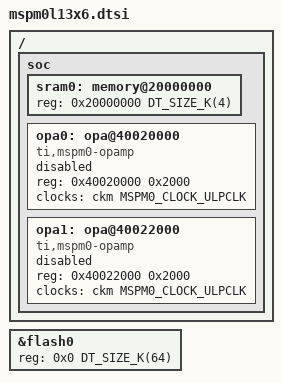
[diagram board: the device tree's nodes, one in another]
/*
 * Copyright (c) 2025 Texas Instruments
 * Copyright (c) 2025 Linumiz GmbH
 *
 * SPDX-License-Identifier: Apache-2.0
 */

#include <mem.h>
#include <ti/mspm0/l/mspm0l.dtsi>

/ {
	soc {
		sram0: memory@20000000 {
			reg = <0x20000000 DT_SIZE_K(4)>;
		};

		opa0: opa@40020000 {
compatible = "ti,mspm0-opamp";
reg = <0x40020000 0x2000>;
clocks = <&ckm MSPM0_CLOCK_ULPCLK>;
status = "disabled";
};

		opa1: opa@40022000 {
compatible = "ti,mspm0-opamp";
reg = <0x40022000 0x2000>;
clocks = <&ckm MSPM0_CLOCK_ULPCLK>;
status = "disabled";
};
	};
};

&flash0 {
	reg = <0x0 DT_SIZE_K(64)>;
	ranges = <0x0 0x0 DT_SIZE_K(64)>;
};
